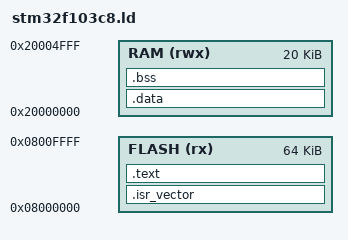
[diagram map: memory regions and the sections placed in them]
/* Blue Pill (STM32F103C8): 64K flash / 20K RAM. Most C8 dies carry a working
 * 128K but we assume the datasheet 64K — the rig has no payload arrays. */
MEMORY
{
  FLASH (rx)  : ORIGIN = 0x08000000, LENGTH = 64K
  RAM   (rwx) : ORIGIN = 0x20000000, LENGTH = 20K
}

ENTRY(Reset_Handler)

SECTIONS
{
  .isr_vector : { KEEP(*(.isr_vector)) } > FLASH

  .text : {
    *(.text*)
    *(.rodata*)
    . = ALIGN(4);
    _etext = .;
  } > FLASH

  .data : AT (_etext) {
    . = ALIGN(4);
    _sdata = .;
    *(.data*)
    . = ALIGN(4);
    _edata = .;
  } > RAM

  .bss : {
    . = ALIGN(4);
    _sbss = .;
    *(.bss*)
    *(COMMON)
    . = ALIGN(4);
    _ebss = .;
  } > RAM

  _estack = ORIGIN(RAM) + LENGTH(RAM);
}
